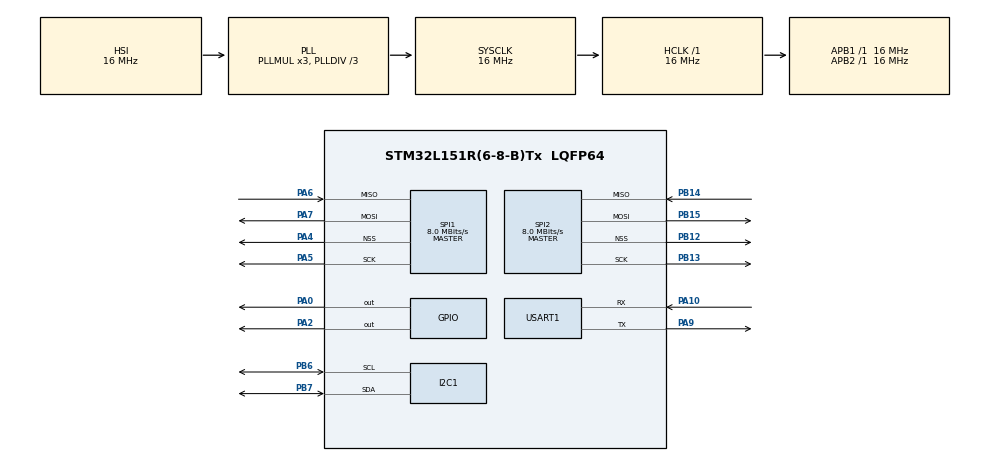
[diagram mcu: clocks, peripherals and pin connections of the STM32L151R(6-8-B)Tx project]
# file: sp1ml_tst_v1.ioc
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Mcu.Family=STM32L1
Mcu.Name=STM32L151R(6-8-B)Tx
Mcu.Package=LQFP64
NVIC.I2C1_ER_IRQn=true\:0\:0\:false\:false\:true
NVIC.I2C1_EV_IRQn=true\:0\:0\:false\:false\:true
NVIC.PriorityGroup=NVIC_PRIORITYGROUP_4
NVIC.RCC_IRQn=true\:0\:0\:false\:false\:true
NVIC.SPI1_IRQn=true\:0\:0\:false\:false\:true
NVIC.SPI2_IRQn=true\:0\:0\:false\:false\:true
NVIC.USART1_IRQn=true\:0\:0\:false\:false\:true
PA0-WKUP1.Signal=GPIO_Output
PA10.Mode=Asynchronous
PA10.Signal=USART1_RX
PA2.Signal=GPIO_Output
PA4.Mode=NSS_Signal_Hard_Output
PA4.Signal=SPI1_NSS
PA5.Mode=Full_Duplex_Master
PA5.Signal=SPI1_SCK
PA6.Mode=Full_Duplex_Master
PA6.Signal=SPI1_MISO
PA7.Mode=Full_Duplex_Master
PA7.Signal=SPI1_MOSI
PA9.Mode=Asynchronous
PA9.Signal=USART1_TX
PB12.Mode=NSS_Signal_Hard_Output
PB12.Signal=SPI2_NSS
PB13.Mode=Full_Duplex_Master
PB13.Signal=SPI2_SCK
PB14.Mode=Full_Duplex_Master
PB14.Signal=SPI2_MISO
PB15.Mode=Full_Duplex_Master
PB15.Signal=SPI2_MOSI
PB6.Mode=I2C
PB6.Signal=I2C1_SCL
PB7.Mode=I2C
PB7.Signal=I2C1_SDA
ProjectManager.HeapSize=0x200
ProjectManager.StackSize=0x400
ProjectManager.TargetToolchain=EWARM
RCC.AHBFreq_Value=16000000
RCC.APB1Freq_Value=16000000
RCC.APB1TimFreq_Value=16000000
RCC.APB2Freq_Value=16000000
RCC.APB2TimFreq_Value=16000000
RCC.HCLKFreq_Value=16000000
RCC.HSE_VALUE=24000000
RCC.HSI_VALUE=16000000
RCC.LSE_VALUE=32768
RCC.MSIClockRange=RCC_MSIRANGE_6
RCC.MSI_VALUE=4194000
RCC.PLLDIV=RCC_PLL_DIV3
RCC.SYSCLKFreq_VALUE=16000000
RCC.SYSCLKSource=RCC_SYSCLKSOURCE_PLLCLK
RCC.USBOutput=24000000
RCC.VCOOutputFreq_Value=48000000
SPI1.CalculateBaudRate=8.0 MBits/s
SPI1.Direction=SPI_DIRECTION_2LINES
SPI1.Mode=SPI_MODE_MASTER
SPI1.VirtualNSS=VM_NSSHARD
SPI1.VirtualType=VM_MASTER
SPI2.CalculateBaudRate=8.0 MBits/s
SPI2.Direction=SPI_DIRECTION_2LINES
SPI2.Mode=SPI_MODE_MASTER
SPI2.VirtualNSS=VM_NSSHARD
SPI2.VirtualType=VM_MASTER
USART1.VirtualMode=VM_ASYNC
board=sp1ml_tst_v1

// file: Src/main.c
/**
  ******************************************************************************
  * File Name          : main.c
  * Description        : Main program body
  ******************************************************************************
  ** This notice applies to any and all portions of this file
  * that are not between comment pairs USER CODE BEGIN and
  * USER CODE END. Other portions of this file, whether
  * inserted by the user or by software development tools
  * are owned by their respective copyright owners.
  *
  * COPYRIGHT(c) 2017 STMicroelectronics
  *
  * Redistribution and use in source and binary forms, with or without modification,
  * are permitted provided that the following conditions are met:
  *   1. Redistributions of source code must retain the above copyright notice,
  *      this list of conditions and the following disclaimer.
  *   2. Redistributions in binary form must reproduce the above copyright notice,
  *      this list of conditions and the following disclaimer in the documentation
  *      and/or other materials provided with the distribution.
  *   3. Neither the name of STMicroelectronics nor the names of its contributors
  *      may be used to endorse or promote products derived from this software
  *      without specific prior written permission.
  *
  * THIS SOFTWARE IS PROVIDED BY THE COPYRIGHT HOLDERS AND CONTRIBUTORS "AS IS"
  * AND ANY EXPRESS OR IMPLIED WARRANTIES, INCLUDING, BUT NOT LIMITED TO, THE
  * IMPLIED WARRANTIES OF MERCHANTABILITY AND FITNESS FOR A PARTICULAR PURPOSE ARE
  * DISCLAIMED. IN NO EVENT SHALL THE COPYRIGHT HOLDER OR CONTRIBUTORS BE LIABLE
  * FOR ANY DIRECT, INDIRECT, INCIDENTAL, SPECIAL, EXEMPLARY, OR CONSEQUENTIAL
  * DAMAGES (INCLUDING, BUT NOT LIMITED TO, PROCUREMENT OF SUBSTITUTE GOODS OR
  * SERVICES; LOSS OF USE, DATA, OR PROFITS; OR BUSINESS INTERRUPTION) HOWEVER
  * CAUSED AND ON ANY THEORY OF LIABILITY, WHETHER IN CONTRACT, STRICT LIABILITY,
  * OR TORT (INCLUDING NEGLIGENCE OR OTHERWISE) ARISING IN ANY WAY OUT OF THE USE
  * OF THIS SOFTWARE, EVEN IF ADVISED OF THE POSSIBILITY OF SUCH DAMAGE.
  *
  ******************************************************************************
  */
#include "main.h"
#include "stm32l1xx_hal.h"

I2C_HandleTypeDef hi2c1;

SPI_HandleTypeDef hspi1;
SPI_HandleTypeDef hspi2;

UART_HandleTypeDef huart1;

/* USER CODE BEGIN PV */
/* Private variables ---------------------------------------------------------*/

/* USER CODE END PV */

void SystemClock_Config(void);
static void MX_GPIO_Init(void);
static void MX_I2C1_Init(void);
static void MX_SPI1_Init(void);
static void MX_SPI2_Init(void);
static void MX_USART1_UART_Init(void);

/* USER CODE BEGIN PFP */
/* Private function prototypes -----------------------------------------------*/

/* USER CODE END PFP */

int main(void)
{

  /* USER CODE BEGIN 1 */
    __HAL_UART_ENABLE_IT(&huart1, UART_IT_RXNE);

  /* USER CODE END 1 */

  /* MCU Configuration----------------------------------------------------------*/

  /* Reset of all peripherals, Initializes the Flash interface and the Systick. */
  HAL_Init();

  /* Configure the system clock */
  SystemClock_Config();

  /* Initialize all configured peripherals */
  MX_GPIO_Init();
  MX_I2C1_Init();
  MX_SPI1_Init();
  MX_SPI2_Init();
  MX_USART1_UART_Init();

  /* Infinite loop */
  while (1)
  {

  /* USER CODE BEGIN 3 */
    HAL_UART_Transmit(&huart1, "Test\r", 5, 200);
    HAL_Delay(300);
    HAL_GPIO_TogglePin(GPIOA, GPIO_PIN_2);
    HAL_GPIO_TogglePin(GPIOA, GPIO_PIN_0);

  }
  /* USER CODE END 3 */

}

/** System Clock Configuration
*/
void SystemClock_Config(void)
{

  RCC_OscInitTypeDef RCC_OscInitStruct;
  RCC_ClkInitTypeDef RCC_ClkInitStruct;

    /**Configure the main internal regulator output voltage
    */
  __HAL_PWR_VOLTAGESCALING_CONFIG(PWR_REGULATOR_VOLTAGE_SCALE1);

    /**Initializes the CPU, AHB and APB busses clocks
    */
  RCC_OscInitStruct.OscillatorType = RCC_OSCILLATORTYPE_HSI;
  RCC_OscInitStruct.HSIState = RCC_HSI_ON;
  RCC_OscInitStruct.HSICalibrationValue = 16;
  RCC_OscInitStruct.PLL.PLLState = RCC_PLL_ON;
  RCC_OscInitStruct.PLL.PLLSource = RCC_PLLSOURCE_HSI;
  RCC_OscInitStruct.PLL.PLLMUL = RCC_PLL_MUL3;
  RCC_OscInitStruct.PLL.PLLDIV = RCC_PLL_DIV3;
  if (HAL_RCC_OscConfig(&RCC_OscInitStruct) != HAL_OK)
  {
    _Error_Handler(__FILE__, __LINE__);
  }

    /**Initializes the CPU, AHB and APB busses clocks
    */
  RCC_ClkInitStruct.ClockType = RCC_CLOCKTYPE_HCLK|RCC_CLOCKTYPE_SYSCLK
                              |RCC_CLOCKTYPE_PCLK1|RCC_CLOCKTYPE_PCLK2;
  RCC_ClkInitStruct.SYSCLKSource = RCC_SYSCLKSOURCE_PLLCLK;
  RCC_ClkInitStruct.AHBCLKDivider = RCC_SYSCLK_DIV1;
  RCC_ClkInitStruct.APB1CLKDivider = RCC_HCLK_DIV1;
  RCC_ClkInitStruct.APB2CLKDivider = RCC_HCLK_DIV1;

  if (HAL_RCC_ClockConfig(&RCC_ClkInitStruct, FLASH_LATENCY_0) != HAL_OK)
  {
    _Error_Handler(__FILE__, __LINE__);
  }

    /**Configure the Systick interrupt time
    */
  HAL_SYSTICK_Config(HAL_RCC_GetHCLKFreq()/1000);

    /**Configure the Systick
    */
  HAL_SYSTICK_CLKSourceConfig(SYSTICK_CLKSOURCE_HCLK);

  /* SysTick_IRQn interrupt configuration */
  HAL_NVIC_SetPriority(SysTick_IRQn, 0, 0);
}

/* I2C1 init function */
static void MX_I2C1_Init(void)
{

  hi2c1.Instance = I2C1;
  hi2c1.Init.ClockSpeed = 100000;
  hi2c1.Init.DutyCycle = I2C_DUTYCYCLE_2;
  hi2c1.Init.OwnAddress1 = 0;
  hi2c1.Init.AddressingMode = I2C_ADDRESSINGMODE_7BIT;
  hi2c1.Init.DualAddressMode = I2C_DUALADDRESS_DISABLE;
  hi2c1.Init.OwnAddress2 = 0;
  hi2c1.Init.GeneralCallMode = I2C_GENERALCALL_DISABLE;
  hi2c1.Init.NoStretchMode = I2C_NOSTRETCH_DISABLE;
  if (HAL_I2C_Init(&hi2c1) != HAL_OK)
  {
    _Error_Handler(__FILE__, __LINE__);
  }

}

/* SPI1 init function */
static void MX_SPI1_Init(void)
{

  hspi1.Instance = SPI1;
  hspi1.Init.Mode = SPI_MODE_MASTER;
  hspi1.Init.Direction = SPI_DIRECTION_2LINES;
  hspi1.Init.DataSize = SPI_DATASIZE_8BIT;
  hspi1.Init.CLKPolarity = SPI_POLARITY_LOW;
  hspi1.Init.CLKPhase = SPI_PHASE_1EDGE;
  hspi1.Init.NSS = SPI_NSS_HARD_OUTPUT;
  hspi1.Init.BaudRatePrescaler = SPI_BAUDRATEPRESCALER_2;
  hspi1.Init.FirstBit = SPI_FIRSTBIT_MSB;
  hspi1.Init.TIMode = SPI_TIMODE_DISABLE;
  hspi1.Init.CRCCalculation = SPI_CRCCALCULATION_DISABLE;
  hspi1.Init.CRCPolynomial = 10;
  if (HAL_SPI_Init(&hspi1) != HAL_OK)
  {
    _Error_Handler(__FILE__, __LINE__);
  }

}

/* SPI2 init function */
static void MX_SPI2_Init(void)
{

  hspi2.Instance = SPI2;
  hspi2.Init.Mode = SPI_MODE_MASTER;
  hspi2.Init.Direction = SPI_DIRECTION_2LINES;
  hspi2.Init.DataSize = SPI_DATASIZE_8BIT;
  hspi2.Init.CLKPolarity = SPI_POLARITY_LOW;
  hspi2.Init.CLKPhase = SPI_PHASE_1EDGE;
  hspi2.Init.NSS = SPI_NSS_HARD_OUTPUT;
  hspi2.Init.BaudRatePrescaler = SPI_BAUDRATEPRESCALER_2;
  hspi2.Init.FirstBit = SPI_FIRSTBIT_MSB;
  hspi2.Init.TIMode = SPI_TIMODE_DISABLE;
  hspi2.Init.CRCCalculation = SPI_CRCCALCULATION_DISABLE;
  hspi2.Init.CRCPolynomial = 10;
  if (HAL_SPI_Init(&hspi2) != HAL_OK)
  {
    _Error_Handler(__FILE__, __LINE__);
  }

}

/* USART1 init function */
static void MX_USART1_UART_Init(void)
{

  huart1.Instance = USART1;
  huart1.Init.BaudRate = 115200;
  huart1.Init.WordLength = UART_WORDLENGTH_8B;
  huart1.Init.StopBits = UART_STOPBITS_1;
  huart1.Init.Parity = UART_PARITY_NONE;
  huart1.Init.Mode = UART_MODE_TX_RX;
  huart1.Init.HwFlowCtl = UART_HWCONTROL_NONE;
  huart1.Init.OverSampling = UART_OVERSAMPLING_16;
  if (HAL_UART_Init(&huart1) != HAL_OK)
  {
    _Error_Handler(__FILE__, __LINE__);
  }

}

/** Configure pins as
        * Analog
        * Input
        * Output
        * EVENT_OUT
        * EXTI
*/
static void MX_GPIO_Init(void)
{

  GPIO_InitTypeDef GPIO_InitStruct;

  /* GPIO Ports Clock Enable */
  __HAL_RCC_GPIOA_CLK_ENABLE();
  __HAL_RCC_GPIOB_CLK_ENABLE();

  /*Configure GPIO pin Output Level */
  HAL_GPIO_WritePin(GPIOA, GPIO_PIN_0|GPIO_PIN_2, GPIO_PIN_RESET);

  /*Configure GPIO pins : PA0 PA2 */
  GPIO_InitStruct.Pin = GPIO_PIN_0|GPIO_PIN_2;
  GPIO_InitStruct.Mode = GPIO_MODE_OUTPUT_PP;
  GPIO_InitStruct.Pull = GPIO_NOPULL;
  GPIO_InitStruct.Speed = GPIO_SPEED_FREQ_LOW;
  HAL_GPIO_Init(GPIOA, &GPIO_InitStruct);

}

void _Error_Handler(char * file, int line)
{
  while(1)
  {
  }
}

/************************ (C) COPYRIGHT STMicroelectronics *****END OF FILE****/
